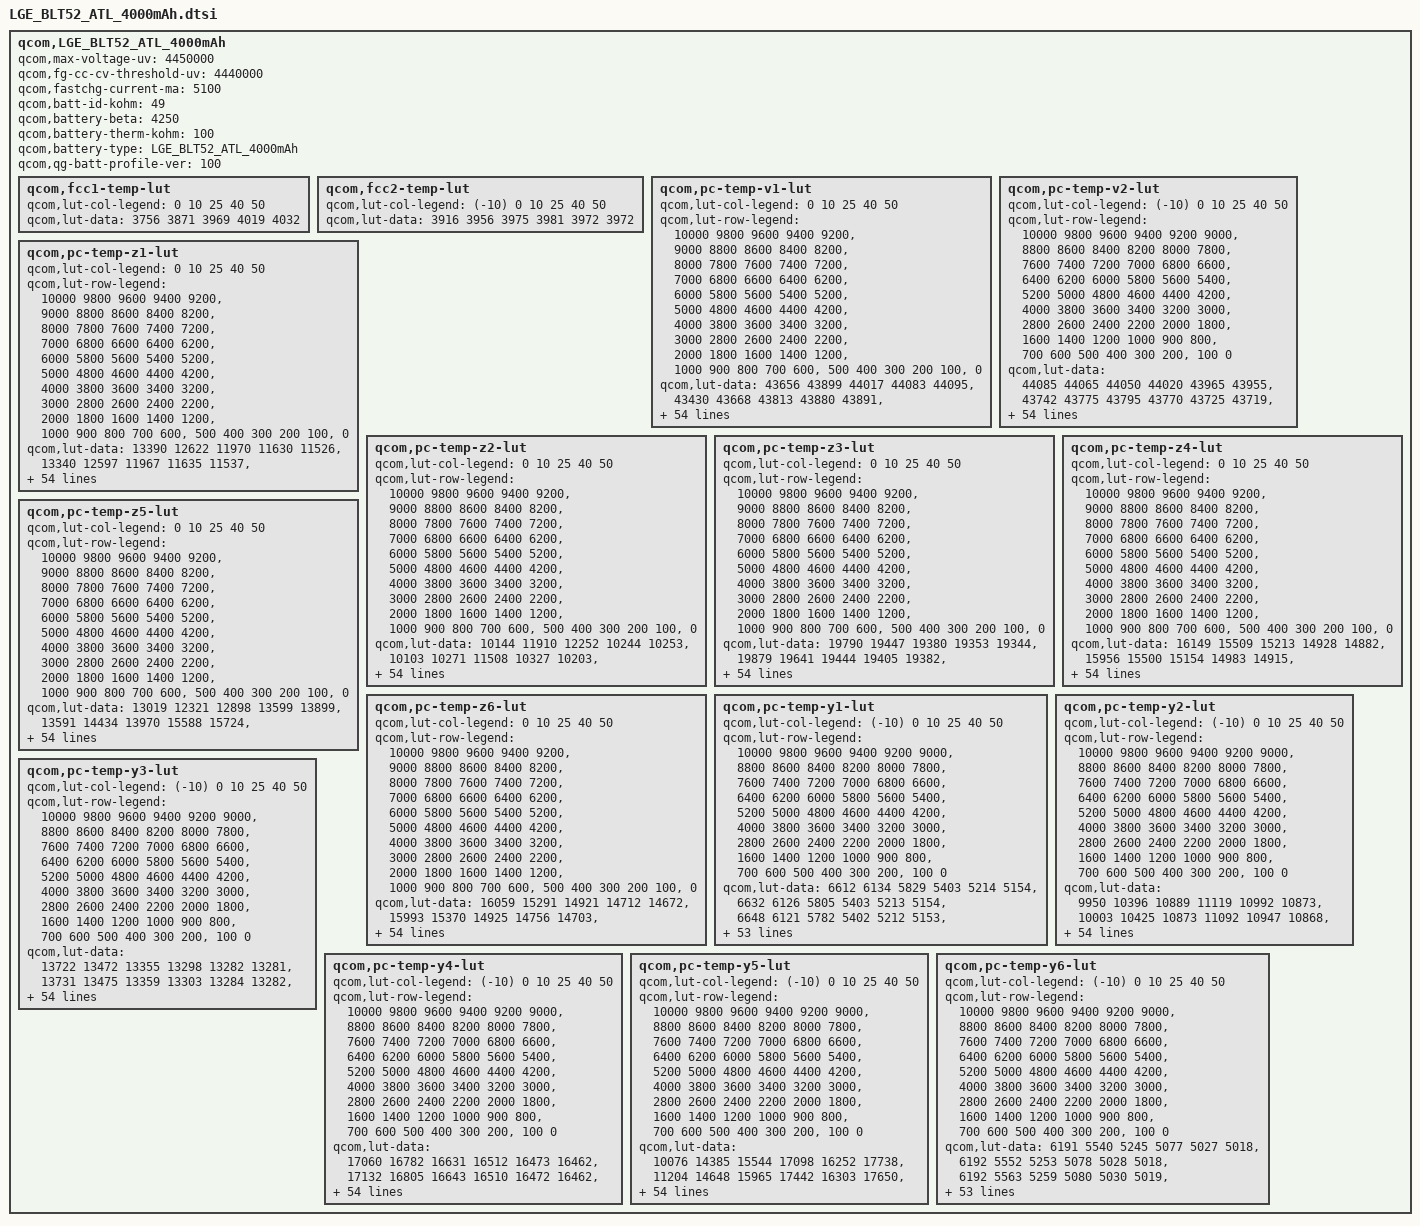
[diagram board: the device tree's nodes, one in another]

qcom,LGE_BLT52_ATL_4000mAh {
    /* 4569428_LGE_WingU_4000mAh_averaged_MasterSlave_Jun8th2020 */
    qcom,max-voltage-uv = <4450000>;
    qcom,fg-cc-cv-threshold-uv = <4440000>;
    qcom,fastchg-current-ma = <5100>;
    qcom,batt-id-kohm = <49>;
    qcom,battery-beta = <4250>;
    qcom,battery-therm-kohm = <100>;
    qcom,battery-type = "LGE_BLT52_ATL_4000mAh";
    qcom,qg-batt-profile-ver = <100>;

	qcom,fcc1-temp-lut {
		qcom,lut-col-legend = <0 10 25 40 50>;
		qcom,lut-data = <3756 3871 3969 4019 4032>;
	};

	qcom,fcc2-temp-lut {
		qcom,lut-col-legend = <(-10) 0 10 25 40 50>;
		qcom,lut-data = <3916 3956 3975 3981 3972 3972>;
	};

	qcom,pc-temp-v1-lut {
		qcom,lut-col-legend = <0 10 25 40 50>;
		qcom,lut-row-legend = <10000 9800 9600 9400 9200>,
			<9000 8800 8600 8400 8200>,
			<8000 7800 7600 7400 7200>,
			<7000 6800 6600 6400 6200>,
			<6000 5800 5600 5400 5200>,
			<5000 4800 4600 4400 4200>,
			<4000 3800 3600 3400 3200>,
			<3000 2800 2600 2400 2200>,
			<2000 1800 1600 1400 1200>,
			<1000 900 800 700 600>,
			<500 400 300 200 100>,
			<0>;
		qcom,lut-data = <43656 43899 44017 44083 44095>,
			<43430 43668 43813 43880 43891>,
			<43200 43445 43603 43676 43693>,
			<42968 43223 43383 43467 43489>,
			<42735 42994 43156 43251 43272>,
			<42502 42756 42923 43028 43048>,
			<42269 42518 42681 42795 42818>,
			<42040 42282 42438 42553 42581>,
			<41817 42047 42199 42312 42344>,
			<41599 41818 41960 42072 42104>,
			<41387 41595 41728 41835 41866>,
			<41180 41378 41501 41604 41635>,
			<40979 41166 41279 41377 41408>,
			<40782 40961 41064 41155 41186>,
			<40582 40759 40852 40937 40967>,
			<40388 40561 40650 40728 40756>,
			<40209 40369 40454 40527 40553>,
			<40040 40193 40267 40335 40357>,
			<39880 40032 40096 40153 40173>,
			<39733 39866 39938 39988 40006>,
			<39592 39689 39748 39812 39834>,
			<39435 39502 39475 39569 39607>,
			<39251 39291 39205 39289 39338>,
			<39064 39028 39029 39091 39133>,
			<38897 38813 38895 38958 38991>,
			<38736 38713 38784 38844 38868>,
			<38614 38648 38693 38734 38747>,
			<38541 38584 38612 38631 38635>,
			<38485 38519 38529 38535 38534>,
			<38436 38456 38448 38441 38442>,
			<38391 38396 38375 38356 38358>,
			<38351 38336 38308 38281 38279>,
			<38313 38283 38248 38213 38206>,
			<38280 38237 38192 38150 38137>,
			<38246 38195 38140 38094 38074>,
			<38213 38155 38092 38040 38011>,
			<38178 38120 38050 37986 37945>,
			<38133 38078 38008 37930 37876>,
			<38062 38007 37943 37859 37796>,
			<37974 37911 37850 37768 37700>,
			<37870 37805 37744 37664 37594>,
			<37741 37684 37628 37548 37479>,
			<37594 37545 37494 37415 37349>,
			<37429 37375 37330 37252 37185>,
			<37296 37222 37181 37111 37049>,
			<37206 37125 37080 37024 36964>,
			<37170 37097 37052 36997 36940>,
			<37136 37074 37035 36980 36923>,
			<37107 37058 37013 36963 36903>,
			<37056 37011 36975 36914 36847>,
			<36873 36815 36755 36675 36586>,
			<36436 36372 36321 36241 36152>,
			<35867 35793 35757 35673 35583>,
			<35085 34993 34985 34903 34813>,
			<33748 33648 33788 33709 33616>,
			<30000 30000 30000 30000 30000>;
	};

	qcom,pc-temp-v2-lut {
		qcom,lut-col-legend = <(-10) 0 10 25 40 50>;
		qcom,lut-row-legend = <10000 9800 9600 9400 9200 9000>,
			<8800 8600 8400 8200 8000 7800>,
			<7600 7400 7200 7000 6800 6600>,
			<6400 6200 6000 5800 5600 5400>,
			<5200 5000 4800 4600 4400 4200>,
			<4000 3800 3600 3400 3200 3000>,
			<2800 2600 2400 2200 2000 1800>,
			<1600 1400 1200 1000 900 800>,
			<700 600 500 400 300 200>,
			<100 0>;
		qcom,lut-data = <44085 44065 44050 44020 43965 43955>,
			<43742 43775 43795 43770 43725 43719>,
			<43429 43501 43546 43527 43489 43487>,
			<43151 43244 43305 43290 43257 43258>,
			<42908 43005 43075 43061 43031 43034>,
			<42670 42768 42841 42830 42803 42808>,
			<42416 42523 42599 42590 42567 42574>,
			<42160 42277 42355 42347 42328 42336>,
			<41923 42033 42113 42108 42091 42100>,
			<41705 41793 41873 41872 41855 41865>,
			<41494 41556 41638 41639 41623 41633>,
			<41281 41314 41409 41409 41396 41405>,
			<41067 41076 41185 41184 41174 41181>,
			<40840 40882 40972 40966 40958 40964>,
			<40594 40738 40770 40754 40745 40752>,
			<40332 40581 40571 40550 40540 40548>,
			<40050 40335 40371 40352 40344 40352>,
			<39746 40024 40168 40162 40157 40163>,
			<39482 39755 39944 39983 39976 39982>,
			<39271 39532 39689 39821 39810 39814>,
			<39084 39326 39443 39644 39631 39636>,
			<38901 39125 39231 39400 39398 39406>,
			<38724 38934 39039 39127 39137 39151>,
			<38568 38764 38870 38922 38936 38953>,
			<38431 38620 38720 38767 38783 38801>,
			<38313 38483 38585 38636 38654 38671>,
			<38224 38329 38463 38516 38539 38553>,
			<38157 38168 38352 38409 38437 38447>,
			<38098 38062 38251 38312 38343 38351>,
			<38040 38002 38159 38220 38253 38262>,
			<37985 37957 38072 38137 38171 38181>,
			<37930 37913 37983 38061 38100 38106>,
			<37874 37874 37897 37990 38036 38037>,
			<37816 37833 37834 37925 37968 37963>,
			<37759 37788 37792 37867 37894 37883>,
			<37701 37740 37753 37808 37815 37795>,
			<37638 37689 37712 37739 37724 37694>,
			<37571 37632 37670 37664 37622 37580>,
			<37499 37566 37616 37586 37526 37477>,
			<37415 37487 37542 37507 37441 37390>,
			<37320 37393 37450 37421 37355 37303>,
			<37229 37278 37339 37318 37254 37201>,
			<37146 37139 37201 37200 37140 37086>,
			<37064 37000 37035 37060 37006 36954>,
			<36984 36871 36884 36936 36895 36844>,
			<36893 36776 36796 36870 36844 36795>,
			<36845 36743 36766 36854 36832 36783>,
			<36797 36710 36732 36837 36819 36770>,
			<36738 36666 36683 36810 36797 36745>,
			<36661 36593 36588 36747 36724 36661>,
			<36533 36395 36359 36530 36476 36384>,
			<36266 35938 35912 36087 36005 35905>,
			<35775 35253 35275 35493 35405 35296>,
			<35022 34240 34380 34709 34593 34477>,
			<33889 32793 33037 33577 33438 33295>,
			<32352 29799 29518 29518 29519 29524>;
	};

	qcom,pc-temp-z1-lut {
		qcom,lut-col-legend = <0 10 25 40 50>;
		qcom,lut-row-legend = <10000 9800 9600 9400 9200>,
			<9000 8800 8600 8400 8200>,
			<8000 7800 7600 7400 7200>,
			<7000 6800 6600 6400 6200>,
			<6000 5800 5600 5400 5200>,
			<5000 4800 4600 4400 4200>,
			<4000 3800 3600 3400 3200>,
			<3000 2800 2600 2400 2200>,
			<2000 1800 1600 1400 1200>,
			<1000 900 800 700 600>,
			<500 400 300 200 100>,
			<0>;
		qcom,lut-data = <13390 12622 11970 11630 11526>,
			<13340 12597 11967 11635 11537>,
			<13314 12589 11963 11636 11539>,
			<13318 12581 11956 11635 11539>,
			<13326 12574 11947 11632 11538>,
			<13329 12568 11938 11629 11537>,
			<13312 12561 11929 11625 11536>,
			<13289 12548 11922 11622 11536>,
			<13278 12531 11917 11620 11536>,
			<13272 12522 11913 11619 11536>,
			<13267 12519 11911 11618 11536>,
			<13261 12517 11910 11618 11536>,
			<13255 12512 11909 11618 11538>,
			<13250 12504 11910 11618 11539>,
			<13242 12500 11911 11619 11539>,
			<13234 12500 11913 11620 11540>,
			<13231 12502 11913 11622 11541>,
			<13233 12502 11914 11623 11544>,
			<13235 12500 11916 11625 11547>,
			<13234 12499 11920 11628 11549>,
			<13230 12503 11923 11630 11551>,
			<13228 12509 11926 11632 11552>,
			<13223 12515 11929 11634 11554>,
			<13221 12523 11933 11636 11556>,
			<13227 12529 11938 11640 11559>,
			<13247 12531 11943 11644 11562>,
			<13260 12533 11948 11648 11566>,
			<13252 12534 11954 11652 11569>,
			<13239 12535 11960 11657 11573>,
			<13235 12536 11966 11660 11577>,
			<13239 12537 11971 11664 11581>,
			<13248 12539 11977 11669 11585>,
			<13263 12541 11981 11673 11590>,
			<13289 12546 11986 11677 11593>,
			<13305 12553 11991 11682 11597>,
			<13296 12562 11996 11686 11600>,
			<13280 12575 12000 11690 11602>,
			<13275 12584 12004 11693 11605>,
			<13286 12588 12010 11696 11607>,
			<13299 12591 12017 11700 11610>,
			<13307 12593 12025 11704 11613>,
			<13312 12603 12038 11707 11616>,
			<13325 12612 12047 11711 11619>,
			<13350 12619 12050 11715 11621>,
			<13330 12636 12058 11722 11625>,
			<13344 12624 12069 11725 11627>,
			<13344 12630 12071 11724 11627>,
			<13331 12621 12071 11725 11627>,
			<13345 12624 12074 11726 11628>,
			<13364 12623 12080 11730 11631>,
			<13365 12636 12090 11734 11636>,
			<13377 12654 12093 11745 11644>,
			<13396 12702 12112 11757 11654>,
			<13442 12722 12139 11776 11669>,
			<13442 12722 12139 11776 11669>,
			<13442 12722 12139 11776 11669>;
	};

	qcom,pc-temp-z2-lut {
		qcom,lut-col-legend = <0 10 25 40 50>;
		qcom,lut-row-legend = <10000 9800 9600 9400 9200>,
			<9000 8800 8600 8400 8200>,
			<8000 7800 7600 7400 7200>,
			<7000 6800 6600 6400 6200>,
			<6000 5800 5600 5400 5200>,
			<5000 4800 4600 4400 4200>,
			<4000 3800 3600 3400 3200>,
			<3000 2800 2600 2400 2200>,
			<2000 1800 1600 1400 1200>,
			<1000 900 800 700 600>,
			<500 400 300 200 100>,
			<0>;
		qcom,lut-data = <10144 11910 12252 10244 10253>,
			<10103 10271 11508 10327 10203>,
			<10069 10230 11015 10367 10279>,
			<10040 10206 10822 10413 10321>,
			<10015 10178 10690 10599 10306>,
			<10001 10145 10543 10764 10276>,
			<9993 10119 10348 10641 10238>,
			<9987 10103 10220 10331 10187>,
			<9984 10091 10212 10235 10165>,
			<9982 10088 10214 10459 10180>,
			<9981 10091 10228 10673 10198>,
			<9982 10096 10348 10671 10177>,
			<9985 10111 10476 10640 10101>,
			<9988 10147 10519 10631 10067>,
			<9991 10176 10547 10661 10080>,
			<9997 10192 10552 10702 10098>,
			<10012 10205 10443 10743 10109>,
			<10049 10222 10333 10788 10120>,
			<10084 10241 10335 10772 10133>,
			<10104 10256 10350 10478 10151>,
			<10120 10262 10366 10220 10176>,
			<10132 10267 10394 10277 10232>,
			<10139 10272 10418 10414 10325>,
			<10146 10279 10402 10443 10360>,
			<10153 10284 10345 10335 10326>,
			<10162 10280 10321 10245 10298>,
			<10170 10268 10351 10300 10372>,
			<10178 10264 10393 10419 10519>,
			<10186 10275 10416 10468 10551>,
			<10193 10291 10434 10467 10393>,
			<10200 10300 10440 10447 10224>,
			<10207 10308 10420 10392 10155>,
			<10215 10312 10395 10320 10106>,
			<10225 10313 10393 10305 10099>,
			<10232 10315 10395 10323 10127>,
			<10238 10316 10400 10352 10170>,
			<10243 10321 10409 10397 10226>,
			<10250 10328 10423 10455 10293>,
			<10263 10341 10442 10491 10339>,
			<10279 10361 10470 10513 10375>,
			<10296 10375 10494 10532 10392>,
			<10315 10381 10509 10554 10385>,
			<10343 10391 10518 10568 10373>,
			<10392 10425 10518 10557 10400>,
			<10593 10639 10586 10520 10394>,
			<10375 10685 10618 10424 10353>,
			<10307 10709 10595 10402 10351>,
			<10266 10759 10584 10398 10355>,
			<10227 11049 10584 10435 10379>,
			<10192 11104 10621 10515 10483>,
			<10162 11055 10704 10502 10338>,
			<10063 10905 10677 10305 10137>,
			<9871 10760 10807 10240 10102>,
			<9781 10475 10800 10187 10036>,
			<9781 10475 10800 10187 10036>,
			<9781 10475 10800 10187 10036>;
	};

	qcom,pc-temp-z3-lut {
		qcom,lut-col-legend = <0 10 25 40 50>;
		qcom,lut-row-legend = <10000 9800 9600 9400 9200>,
			<9000 8800 8600 8400 8200>,
			<8000 7800 7600 7400 7200>,
			<7000 6800 6600 6400 6200>,
			<6000 5800 5600 5400 5200>,
			<5000 4800 4600 4400 4200>,
			<4000 3800 3600 3400 3200>,
			<3000 2800 2600 2400 2200>,
			<2000 1800 1600 1400 1200>,
			<1000 900 800 700 600>,
			<500 400 300 200 100>,
			<0>;
		qcom,lut-data = <19790 19447 19380 19353 19344>,
			<19879 19641 19444 19405 19382>,
			<19936 19678 19490 19429 19398>,
			<19958 19698 19518 19444 19409>,
			<19971 19707 19539 19458 19419>,
			<19978 19712 19544 19466 19427>,
			<19982 19715 19539 19462 19428>,
			<19984 19714 19533 19453 19428>,
			<19982 19713 19527 19450 19428>,
			<19970 19710 19520 19457 19425>,
			<19959 19699 19516 19464 19418>,
			<19953 19683 19517 19457 19410>,
			<19948 19669 19518 19445 19400>,
			<19947 19653 19514 19438 19392>,
			<19950 19642 19509 19434 19388>,
			<19953 19636 19501 19431 19385>,
			<19946 19631 19484 19427 19382>,
			<19912 19627 19468 19421 19379>,
			<19885 19624 19461 19414 19376>,
			<19879 19623 19456 19396 19369>,
			<19876 19626 19456 19383 19364>,
			<19876 19634 19479 19390 19367>,
			<19887 19643 19504 19405 19375>,
			<19899 19655 19499 19407 19377>,
			<19900 19663 19477 19382 19357>,
			<19899 19657 19459 19361 19339>,
			<19897 19641 19448 19367 19360>,
			<19890 19630 19441 19381 19412>,
			<19878 19624 19446 19394 19428>,
			<19867 19621 19464 19418 19421>,
			<19859 19623 19478 19435 19412>,
			<19851 19630 19485 19432 19403>,
			<19843 19635 19490 19424 19395>,
			<19835 19634 19490 19416 19386>,
			<19827 19631 19486 19407 19377>,
			<19820 19628 19481 19399 19370>,
			<19814 19622 19474 19394 19368>,
			<19807 19616 19466 19389 19366>,
			<19797 19609 19460 19385 19365>,
			<19785 19602 19456 19380 19363>,
			<19771 19594 19452 19377 19363>,
			<19752 19586 19450 19382 19363>,
			<19730 19575 19447 19388 19365>,
			<19697 19560 19438 19387 19371>,
			<19477 19506 19418 19379 19368>,
			<19338 19483 19412 19360 19354>,
			<19328 19465 19411 19359 19346>,
			<19325 19441 19399 19358 19342>,
			<19317 19314 19400 19348 19335>,
			<19310 19311 19366 19339 19330>,
			<19311 19317 19369 19343 19352>,
			<19325 19315 19371 19364 19364>,
			<19335 19315 19329 19367 19367>,
			<19360 19350 19326 19368 19366>,
			<19360 19350 19326 19368 19366>,
			<19360 19350 19326 19368 19366>;
	};

	qcom,pc-temp-z4-lut {
		qcom,lut-col-legend = <0 10 25 40 50>;
		qcom,lut-row-legend = <10000 9800 9600 9400 9200>,
			<9000 8800 8600 8400 8200>,
			<8000 7800 7600 7400 7200>,
			<7000 6800 6600 6400 6200>,
			<6000 5800 5600 5400 5200>,
			<5000 4800 4600 4400 4200>,
			<4000 3800 3600 3400 3200>,
			<3000 2800 2600 2400 2200>,
			<2000 1800 1600 1400 1200>,
			<1000 900 800 700 600>,
			<500 400 300 200 100>,
			<0>;
		qcom,lut-data = <16149 15509 15213 14928 14882>,
			<15956 15500 15154 14983 14915>,
			<15784 15412 15095 14950 14894>,
			<15633 15267 15028 14913 14870>,
			<15497 15168 14960 14863 14845>,
			<15385 15095 14918 14822 14819>,
			<15291 15035 14893 14809 14797>,
			<15213 14985 14871 14800 14778>,
			<15154 14943 14845 14789 14762>,
			<15108 14912 14816 14752 14748>,
			<15067 14890 14792 14717 14738>,
			<15028 14871 14765 14711 14734>,
			<14992 14852 14742 14709 14733>,
			<14959 14833 14732 14705 14730>,
			<14925 14821 14722 14696 14724>,
			<14897 14816 14718 14687 14715>,
			<14883 14812 14728 14680 14708>,
			<14876 14803 14739 14675 14701>,
			<14868 14785 14735 14673 14695>,
			<14848 14775 14728 14681 14691>,
			<14823 14778 14727 14696 14689>,
			<14816 14785 14774 14736 14713>,
			<14830 14803 14838 14806 14785>,
			<14854 14878 14874 14847 14830>,
			<14883 14939 14901 14872 14852>,
			<14925 14937 14910 14884 14863>,
			<14949 14924 14903 14872 14834>,
			<14945 14909 14890 14839 14760>,
			<14934 14893 14870 14806 14726>,
			<14922 14876 14837 14761 14718>,
			<14910 14857 14808 14728 14712>,
			<14895 14836 14783 14718 14707>,
			<14881 14820 14763 14712 14701>,
			<14866 14809 14755 14710 14699>,
			<14852 14801 14751 14710 14697>,
			<14837 14792 14749 14710 14697>,
			<14823 14784 14749 14712 14698>,
			<14812 14779 14749 14716 14702>,
			<14802 14780 14751 14722 14708>,
			<14794 14781 14762 14736 14720>,
			<14787 14780 14768 14744 14728>,
			<14781 14767 14756 14732 14722>,
			<14771 14752 14744 14719 14713>,
			<14758 14741 14741 14719 14711>,
			<14852 14711 14719 14709 14701>,
			<14983 14704 14695 14700 14686>,
			<14988 14711 14685 14691 14685>,
			<14987 14727 14677 14674 14669>,
			<14988 14859 14660 14659 14652>,
			<14987 14857 14690 14661 14647>,
			<14980 14855 14710 14692 14667>,
			<14992 14873 14722 14683 14667>,
			<14999 14876 14770 14682 14666>,
			<15000 14855 14775 14681 14667>,
			<15000 14855 14775 14681 14667>,
			<15000 14855 14775 14681 14667>;
	};

	qcom,pc-temp-z5-lut {
		qcom,lut-col-legend = <0 10 25 40 50>;
		qcom,lut-row-legend = <10000 9800 9600 9400 9200>,
			<9000 8800 8600 8400 8200>,
			<8000 7800 7600 7400 7200>,
			<7000 6800 6600 6400 6200>,
			<6000 5800 5600 5400 5200>,
			<5000 4800 4600 4400 4200>,
			<4000 3800 3600 3400 3200>,
			<3000 2800 2600 2400 2200>,
			<2000 1800 1600 1400 1200>,
			<1000 900 800 700 600>,
			<500 400 300 200 100>,
			<0>;
		qcom,lut-data = <13019 12321 12898 13599 13899>,
			<13591 14434 13970 15588 15724>,
			<14057 15037 14876 16657 16550>,
			<14386 15420 15636 17338 17217>,
			<14654 15831 16300 17935 17926>,
			<14976 16226 16684 18324 18532>,
			<15423 16645 16886 18267 18927>,
			<15877 17223 17097 17979 19198>,
			<16194 17858 17526 18173 19509>,
			<16417 18189 18148 21527 20047>,
			<16686 18302 18713 24683 20493>,
			<17113 18413 20294 24501 20241>,
			<17723 18726 22039 23699 19300>,
			<18589 19332 23106 23514 18893>,
			<20511 19942 24132 24779 19199>,
			<22294 20461 24511 26465 19725>,
			<22524 21006 22756 27848 20403>,
			<22462 21630 21010 29150 21333>,
			<22419 22329 21250 29245 21887>,
			<23293 23379 21897 25245 22092>,
			<25722 26252 23404 21798 22169>,
			<29130 30612 33792 24177 22836>,
			<37016 33992 44539 29124 24542>,
			<44344 37052 41898 29803 24685>,
			<45177 38852 30277 22613 19626>,
			<44612 36360 22826 16360 14887>,
			<43731 29898 19925 15932 16339>,
			<41484 26364 18283 16099 20443>,
			<37956 25158 18436 16900 22130>,
			<35623 24502 19701 20002 22059>,
			<34175 25015 21283 23037 21951>,
			<33181 27253 23549 24425 22351>,
			<32718 29381 26198 25408 22984>,
			<32356 30938 28570 25985 23433>,
			<32199 32201 30965 26406 23709>,
			<32455 32764 31936 26602 23979>,
			<33021 33097 31325 26419 24422>,
			<33613 33246 30178 25903 24894>,
			<34719 33115 28907 24984 24746>,
			<35682 32719 27240 22750 22793>,
			<35091 32057 26048 21299 21126>,
			<32728 30325 25597 21929 20784>,
			<31513 29056 25069 22657 20640>,
			<30808 28397 23091 22366 22234>,
			<18969 28760 23495 21989 22218>,
			<12331 26052 24841 19242 19833>,
			<12126 21622 24929 19476 18170>,
			<12047 19848 22718 20717 18664>,
			<11914 12239 25100 20961 20429>,
			<11836 12199 17190 19683 21051>,
			<11936 12413 16639 16375 20048>,
			<11978 12175 15610 17202 19634>,
			<11908 12110 12894 17134 19164>,
			<12603 13070 12639 16466 17681>,
			<12603 13070 12639 16466 17681>,
			<12603 13070 12639 16466 17681>;
	};

	qcom,pc-temp-z6-lut {
		qcom,lut-col-legend = <0 10 25 40 50>;
		qcom,lut-row-legend = <10000 9800 9600 9400 9200>,
			<9000 8800 8600 8400 8200>,
			<8000 7800 7600 7400 7200>,
			<7000 6800 6600 6400 6200>,
			<6000 5800 5600 5400 5200>,
			<5000 4800 4600 4400 4200>,
			<4000 3800 3600 3400 3200>,
			<3000 2800 2600 2400 2200>,
			<2000 1800 1600 1400 1200>,
			<1000 900 800 700 600>,
			<500 400 300 200 100>,
			<0>;
		qcom,lut-data = <16059 15291 14921 14712 14672>,
			<15993 15370 14925 14756 14703>,
			<15927 15337 14921 14757 14704>,
			<15857 15276 14908 14757 14704>,
			<15787 15231 14886 14746 14700>,
			<15727 15194 14867 14731 14692>,
			<15677 15161 14852 14722 14685>,
			<15634 15134 14837 14714 14678>,
			<15597 15110 14821 14705 14670>,
			<15564 15089 14805 14694 14662>,
			<15536 15069 14791 14684 14655>,
			<15511 15051 14780 14676 14648>,
			<15489 15033 14771 14669 14642>,
			<15469 15015 14763 14663 14636>,
			<15453 15003 14757 14657 14631>,
			<15437 14997 14751 14651 14626>,
			<15418 14992 14746 14646 14621>,
			<15396 14985 14741 14641 14616>,
			<15378 14977 14736 14636 14611>,
			<15366 14972 14731 14631 14606>,
			<15356 14975 14730 14629 14603>,
			<15354 14983 14766 14648 14616>,
			<15367 14998 14806 14691 14654>,
			<15385 15038 14813 14704 14668>,
			<15402 15070 14815 14702 14668>,
			<15421 15067 14815 14700 14667>,
			<15432 15054 14809 14697 14665>,
			<15427 15043 14800 14692 14662>,
			<15417 15035 14795 14687 14658>,
			<15408 15027 14791 14682 14652>,
			<15401 15022 14787 14676 14645>,
			<15394 15017 14782 14671 14638>,
			<15386 15013 14777 14665 14632>,
			<15377 15010 14773 14660 14626>,
			<15369 15008 14771 14655 14620>,
			<15362 15004 14768 14652 14617>,
			<15356 14999 14764 14650 14617>,
			<15352 14996 14761 14649 14617>,
			<15349 14996 14761 14649 14618>,
			<15347 14997 14765 14653 14623>,
			<15344 14996 14767 14655 14626>,
			<15339 14991 14763 14653 14624>,
			<15332 14984 14757 14651 14621>,
			<15319 14978 14754 14651 14624>,
			<15254 14949 14738 14644 14619>,
			<15249 14934 14726 14630 14605>,
			<15248 14929 14722 14625 14601>,
			<15246 14925 14712 14617 14592>,
			<15246 14920 14707 14606 14580>,
			<15248 14920 14703 14602 14575>,
			<15254 14931 14716 14619 14597>,
			<15280 14944 14726 14629 14607>,
			<15303 14957 14730 14633 14610>,
			<15345 14983 14738 14637 14614>,
			<15345 14983 14738 14637 14614>,
			<15345 14983 14738 14637 14614>;
	};

	qcom,pc-temp-y1-lut {
		qcom,lut-col-legend = <(-10) 0 10 25 40 50>;
		qcom,lut-row-legend = <10000 9800 9600 9400 9200 9000>,
			<8800 8600 8400 8200 8000 7800>,
			<7600 7400 7200 7000 6800 6600>,
			<6400 6200 6000 5800 5600 5400>,
			<5200 5000 4800 4600 4400 4200>,
			<4000 3800 3600 3400 3200 3000>,
			<2800 2600 2400 2200 2000 1800>,
			<1600 1400 1200 1000 900 800>,
			<700 600 500 400 300 200>,
			<100 0>;
		qcom,lut-data = <6612 6134 5829 5403 5214 5154>,
			<6632 6126 5805 5403 5213 5154>,
			<6648 6121 5782 5402 5212 5153>,
			<6662 6119 5764 5401 5210 5153>,
			<6672 6119 5751 5400 5209 5152>,
			<6678 6122 5746 5399 5208 5152>,
			<6681 6129 5751 5396 5207 5151>,
			<6681 6137 5759 5392 5206 5151>,
			<6679 6138 5760 5388 5205 5150>,
			<6670 6126 5752 5384 5204 5150>,
			<6661 6116 5743 5381 5204 5150>,
			<6662 6118 5737 5382 5203 5151>,
			<6663 6123 5730 5383 5203 5152>,
			<6665 6125 5728 5383 5202 5152>,
			<6680 6120 5729 5382 5203 5152>,
			<6697 6118 5729 5382 5204 5151>,
			<6700 6123 5730 5382 5204 5152>,
			<6701 6131 5731 5383 5205 5153>,
			<6701 6135 5733 5384 5206 5154>,
			<6699 6135 5736 5386 5207 5156>,
			<6698 6135 5740 5388 5208 5157>,
			<6703 6134 5745 5391 5210 5158>,
			<6710 6131 5750 5395 5212 5159>,
			<6713 6131 5751 5399 5214 5161>,
			<6708 6138 5751 5402 5216 5163>,
			<6696 6145 5752 5406 5219 5165>,
			<6686 6146 5757 5411 5221 5167>,
			<6674 6146 5764 5416 5224 5168>,
			<6667 6146 5766 5421 5227 5171>,
			<6679 6148 5766 5426 5230 5174>,
			<6702 6150 5765 5431 5233 5177>,
			<6712 6150 5766 5436 5236 5179>,
			<6715 6149 5766 5442 5240 5182>,
			<6717 6150 5768 5446 5244 5184>,
			<6723 6162 5773 5449 5247 5187>,
			<6733 6175 5779 5452 5250 5189>,
			<6734 6173 5782 5457 5252 5190>,
			<6707 6161 5786 5462 5254 5192>,
			<6681 6156 5790 5465 5256 5193>,
			<6680 6158 5794 5467 5257 5195>,
			<6684 6161 5797 5470 5259 5197>,
			<6687 6167 5801 5473 5261 5199>,
			<6688 6182 5805 5479 5263 5200>,
			<6690 6183 5804 5491 5266 5201>,
			<6706 6184 5803 5500 5269 5203>,
			<6729 6182 5811 5506 5273 5207>,
			<6746 6202 5816 5505 5273 5207>,
			<6768 6203 5824 5506 5273 5207>,
			<6783 6239 5825 5504 5273 5207>,
			<6821 6239 5834 5505 5274 5208>,
			<6878 6276 5847 5507 5274 5210>,
			<6973 6326 5858 5520 5280 5215>,
			<7038 6366 5907 5540 5289 5223>,
			<7187 6520 5952 5566 5300 5231>,
			<7187 6520 5952 5566 5300 5231>,
			<7187 6520 5952 5566 5300 5231>;
	};

	qcom,pc-temp-y2-lut {
		qcom,lut-col-legend = <(-10) 0 10 25 40 50>;
		qcom,lut-row-legend = <10000 9800 9600 9400 9200 9000>,
			<8800 8600 8400 8200 8000 7800>,
			<7600 7400 7200 7000 6800 6600>,
			<6400 6200 6000 5800 5600 5400>,
			<5200 5000 4800 4600 4400 4200>,
			<4000 3800 3600 3400 3200 3000>,
			<2800 2600 2400 2200 2000 1800>,
			<1600 1400 1200 1000 900 800>,
			<700 600 500 400 300 200>,
			<100 0>;
		qcom,lut-data = <9950 10396 10889 11119 10992 10873>,
			<10003 10425 10873 11092 10947 10868>,
			<10053 10459 10858 11063 10903 10855>,
			<10101 10494 10842 11033 10865 10836>,
			<10146 10523 10827 11004 10837 10814>,
			<10187 10541 10812 10978 10821 10793>,
			<10220 10549 10795 10951 10818 10766>,
			<10250 10555 10780 10926 10822 10737>,
			<10307 10553 10778 10918 10821 10718>,
			<10449 10536 10785 10915 10810 10701>,
			<10560 10523 10796 10914 10807 10692>,
			<10552 10595 10808 10924 10832 10697>,
			<10520 10737 10827 10948 10872 10705>,
			<10514 10775 10853 10975 10894 10713>,
			<10618 10756 10898 11010 10905 10743>,
			<10730 10741 10947 11048 10918 10774>,
			<10559 10760 10999 11082 10948 10802>,
			<9988 10812 11048 11118 11000 10852>,
			<9701 10853 11057 11173 11070 10919>,
			<9691 10880 11047 11276 11193 11042>,
			<9685 10906 11040 11342 11276 11126>,
			<9682 10942 11047 11291 11239 11094>,
			<9680 10982 11065 11193 11151 11024>,
			<9677 10990 11080 11170 11102 11003>,
			<9674 10926 11091 11188 11077 11005>,
			<9671 10861 11104 11211 11063 11011>,
			<9670 10867 11128 11229 11104 11030>,
			<9668 10896 11157 11247 11198 11071>,
			<9667 10907 11163 11267 11240 11110>,
			<9667 10873 11141 11291 11242 11156>,
			<9666 10800 11118 11314 11244 11203>,
			<9665 10556 11112 11337 11297 11245>,
			<9664 10003 11109 11360 11397 11283>,
			<9664 9729 11101 11365 11430 11304>,
			<9663 9702 11077 11354 11422 11325>,
			<9663 9687 11043 11338 11407 11337>,
			<9663 9678 11012 11318 11353 11302>,
			<9662 9672 10978 11290 11243 11214>,
			<9662 9668 10937 11261 11197 11146>,
			<9662 9665 10887 11233 11203 11094>,
			<9661 9663 10824 11202 11213 11061>,
			<9661 9662 10751 11166 11214 11067>,
			<9660 9660 10643 11125 11212 11083>,
			<9660 9659 10232 11078 11155 11050>,
			<9659 9659 9815 11008 11021 10935>,
			<9657 9658 9763 10973 10908 10794>,
			<9656 9657 9757 10985 10907 10784>,
			<9655 9657 9707 10966 10965 10780>,
			<9653 9656 9683 10951 10987 10864>,
			<9651 9654 9671 10948 11000 10867>,
			<9649 9652 9663 10926 10949 10776>,
			<9648 9649 9658 10842 10879 10723>,
			<9648 9648 9653 10755 10852 10653>,
			<9647 9648 9650 10664 10743 10543>,
			<9647 9648 9650 10664 10743 10543>,
			<9647 9648 9650 10664 10743 10543>;
	};

	qcom,pc-temp-y3-lut {
		qcom,lut-col-legend = <(-10) 0 10 25 40 50>;
		qcom,lut-row-legend = <10000 9800 9600 9400 9200 9000>,
			<8800 8600 8400 8200 8000 7800>,
			<7600 7400 7200 7000 6800 6600>,
			<6400 6200 6000 5800 5600 5400>,
			<5200 5000 4800 4600 4400 4200>,
			<4000 3800 3600 3400 3200 3000>,
			<2800 2600 2400 2200 2000 1800>,
			<1600 1400 1200 1000 900 800>,
			<700 600 500 400 300 200>,
			<100 0>;
		qcom,lut-data = <13722 13472 13355 13298 13282 13281>,
			<13731 13475 13359 13303 13284 13282>,
			<13735 13477 13364 13307 13285 13283>,
			<13735 13480 13369 13309 13287 13284>,
			<13733 13482 13373 13311 13288 13285>,
			<13728 13484 13376 13312 13290 13286>,
			<13714 13484 13377 13312 13291 13287>,
			<13690 13484 13379 13311 13292 13288>,
			<13681 13483 13379 13311 13294 13289>,
			<13681 13477 13379 13315 13294 13290>,
			<13680 13470 13379 13317 13296 13291>,
			<13648 13461 13376 13318 13299 13292>,
			<13580 13451 13372 13318 13303 13293>,
			<13554 13449 13370 13318 13304 13294>,
			<13560 13452 13368 13320 13304 13296>,
			<13566 13455 13367 13321 13304 13297>,
			<13555 13451 13369 13318 13305 13298>,
			<13521 13441 13373 13313 13307 13299>,
			<13504 13432 13373 13312 13307 13299>,
			<13504 13423 13364 13319 13304 13298>,
			<13504 13415 13355 13324 13301 13297>,
			<13506 13405 13351 13320 13296 13292>,
			<13515 13394 13347 13310 13291 13286>,
			<13520 13387 13344 13306 13287 13284>,
			<13515 13383 13342 13304 13285 13283>,
			<13507 13379 13340 13303 13284 13283>,
			<13509 13367 13338 13303 13285 13282>,
			<13530 13348 13336 13302 13286 13282>,
			<13559 13341 13336 13302 13286 13282>,
			<13588 13344 13335 13302 13285 13283>,
			<13624 13349 13335 13302 13284 13284>,
			<13659 13358 13334 13302 13285 13283>,
			<13695 13377 13332 13301 13288 13283>,
			<13733 13396 13331 13301 13289 13283>,
			<13775 13416 13333 13303 13289 13283>,
			<13820 13438 13336 13304 13288 13284>,
			<13862 13469 13339 13303 13286 13283>,
			<13904 13509 13343 13302 13285 13282>,
			<13942 13557 13346 13302 13285 13281>,
			<13975 13616 13350 13302 13286 13283>,
			<14003 13685 13353 13303 13287 13284>,
			<14036 13758 13356 13304 13288 13285>,
			<14077 13837 13359 13306 13289 13285>,
			<14129 13914 13362 13307 13287 13284>,
			<14203 13990 13372 13309 13285 13282>,
			<14391 14063 13392 13311 13290 13288>,
			<14506 14053 13396 13312 13293 13290>,
			<14581 14164 13432 13317 13299 13294>,
			<15067 14310 13479 13324 13302 13296>,
			<15930 14633 13551 13329 13302 13295>,
			<17884 15308 13678 13326 13296 13290>,
			<22643 17186 13957 13326 13294 13289>,
			<36108 23402 14644 13335 13300 13293>,
			<65535 47011 16544 13350 13305 13300>,
			<65535 47011 16544 13350 13305 13300>,
			<65535 47011 16544 13350 13305 13300>;
	};

	qcom,pc-temp-y4-lut {
		qcom,lut-col-legend = <(-10) 0 10 25 40 50>;
		qcom,lut-row-legend = <10000 9800 9600 9400 9200 9000>,
			<8800 8600 8400 8200 8000 7800>,
			<7600 7400 7200 7000 6800 6600>,
			<6400 6200 6000 5800 5600 5400>,
			<5200 5000 4800 4600 4400 4200>,
			<4000 3800 3600 3400 3200 3000>,
			<2800 2600 2400 2200 2000 1800>,
			<1600 1400 1200 1000 900 800>,
			<700 600 500 400 300 200>,
			<100 0>;
		qcom,lut-data = <17060 16782 16631 16512 16473 16462>,
			<17132 16805 16643 16510 16472 16462>,
			<17200 16855 16661 16509 16472 16462>,
			<17258 16912 16680 16510 16472 16462>,
			<17299 16961 16695 16511 16472 16463>,
			<17316 16982 16701 16513 16473 16463>,
			<17308 16981 16700 16518 16474 16464>,
			<17286 16980 16697 16525 16475 16465>,
			<17260 16980 16697 16528 16477 16466>,
			<17217 16990 16702 16530 16482 16468>,
			<17186 17003 16709 16532 16485 16470>,
			<17227 17015 16723 16539 16486 16474>,
			<17331 17028 16743 16550 16487 16479>,
			<17365 17048 16767 16561 16489 16483>,
			<17238 17091 16801 16573 16498 16488>,
			<17098 17121 16821 16587 16509 16492>,
			<17078 17071 16816 16615 16520 16498>,
			<17074 16948 16801 16648 16532 16508>,
			<17066 16874 16777 16663 16550 16522>,
			<17031 16840 16726 16672 16586 16551>,
			<16975 16813 16675 16675 16611 16572>,
			<16917 16782 16641 16632 16580 16550>,
			<16845 16752 16613 16547 16514 16502>,
			<16810 16724 16599 16515 16487 16479>,
			<16815 16699 16590 16506 16480 16471>,
			<16824 16676 16584 16502 16477 16467>,
			<16827 16650 16581 16504 16479 16469>,
			<16826 16622 16579 16509 16484 16475>,
			<16824 16613 16576 16515 16491 16481>,
			<16820 16618 16571 16521 16502 16488>,
			<16814 16627 16564 16528 16515 16497>,
			<16814 16645 16552 16537 16524 16508>,
			<16821 16679 16536 16545 16533 16522>,
			<16827 16707 16532 16548 16535 16526>,
			<16829 16727 16544 16548 16534 16523>,
			<16829 16742 16563 16548 16531 16518>,
			<16829 16755 16583 16541 16519 16507>,
			<16824 16766 16607 16524 16496 16489>,
			<16819 16770 16626 16518 16485 16482>,
			<16817 16769 16641 16516 16484 16481>,
			<16816 16767 16651 16516 16483 16481>,
			<16816 16758 16650 16520 16483 16480>,
			<16819 16734 16648 16527 16483 16480>,
			<16826 16718 16653 16524 16475 16468>,
			<16843 16709 16660 16521 16467 16454>,
			<16905 16714 16656 16514 16470 16461>,
			<16929 16704 16654 16515 16481 16481>,
			<16894 16718 16680 16532 16502 16511>,
			<17012 16743 16715 16558 16534 16544>,
			<17225 16832 16758 16589 16547 16547>,
			<17649 16990 16774 16567 16509 16494>,
			<18633 17348 16785 16548 16474 16469>,
			<22719 19603 16955 16562 16475 16471>,
			<55470 45558 18096 16605 16494 16485>,
			<55470 45558 18096 16605 16494 16485>,
			<55470 45558 18096 16605 16494 16485>;
	};

	qcom,pc-temp-y5-lut {
		qcom,lut-col-legend = <(-10) 0 10 25 40 50>;
		qcom,lut-row-legend = <10000 9800 9600 9400 9200 9000>,
			<8800 8600 8400 8200 8000 7800>,
			<7600 7400 7200 7000 6800 6600>,
			<6400 6200 6000 5800 5600 5400>,
			<5200 5000 4800 4600 4400 4200>,
			<4000 3800 3600 3400 3200 3000>,
			<2800 2600 2400 2200 2000 1800>,
			<1600 1400 1200 1000 900 800>,
			<700 600 500 400 300 200>,
			<100 0>;
		qcom,lut-data = <10076 14385 15544 17098 16252 17738>,
			<11204 14648 15965 17442 16303 17650>,
			<12453 14909 16294 17531 16315 17555>,
			<13672 15153 16532 17419 16294 17455>,
			<14707 15366 16676 17158 16251 17352>,
			<15405 15535 16727 16801 16191 17249>,
			<15724 15680 16647 16022 16105 17153>,
			<15938 15793 16459 15068 15980 17048>,
			<16452 15794 16238 14808 15789 16902>,
			<18172 15610 15926 14979 15425 16687>,
			<19576 15357 15600 15054 15197 16419>,
			<19004 15013 15251 14708 15628 16032>,
			<17459 14617 14936 14235 16402 15588>,
			<17038 14813 14899 14056 16496 15354>,
			<20250 17493 15167 13998 15749 15397>,
			<23666 19828 15655 13952 15052 15487>,
			<22223 19925 17741 13879 14822 15270>,
			<16730 19844 20984 13804 14674 14859>,
			<14065 19903 21781 14409 14686 14792>,
			<14242 20282 21514 18696 15106 14848>,
			<14490 20602 21231 21953 15768 14941>,
			<14609 20589 21106 21857 16937 15939>,
			<14739 20520 21009 21511 18453 17798>,
			<14786 20580 20877 21083 18748 18329>,
			<13815 21940 20644 20373 17554 18145>,
			<12362 23321 20484 19726 16513 17829>,
			<12066 21384 20561 19311 16515 17088>,
			<12143 15748 20823 18965 16591 15971>,
			<12242 13374 21318 18850 16561 15634>,
			<12436 13487 22902 18891 15949 15678>,
			<12735 13611 24181 18979 15387 15721>,
			<12893 13581 23314 19087 16013 15727>,
			<12955 13453 21068 19284 17642 15728>,
			<13026 13394 19739 19709 18471 15827>,
			<13205 13457 19097 21139 18712 16920>,
			<13496 13579 18697 22249 18879 18069>,
			<13748 13765 18521 21910 19072 18334>,
			<13993 14080 18405 20977 19282 18453>,
			<14155 14305 18289 20118 19342 18692>,
			<13965 14441 18160 19051 19194 19459>,
			<13354 14540 18057 18102 19045 20269>,
			<12973 14495 17955 17561 19112 20656>,
			<12842 14254 17694 17209 19295 20885>,
			<12733 13954 15842 17158 18256 19991>,
			<12670 13543 14150 17125 16798 18535>,
			<12363 13234 14096 17626 16436 17531>,
			<12227 13397 14107 17601 16457 16777>,
			<12478 13644 13981 17397 17447 16651>,
			<12006 13698 13940 17555 17565 16279>,
			<11332 13168 14100 17953 16925 15891>,
			<10554 12106 14121 18059 16527 15931>,
			<9684 10624 13641 18539 18324 17134>,
			<9063 9430 12372 19635 20748 18030>,
			<8820 8861 10231 20822 22452 22785>,
			<8820 8861 10231 20822 22452 22785>,
			<8820 8861 10231 20822 22452 22785>;
	};

	qcom,pc-temp-y6-lut {
		qcom,lut-col-legend = <(-10) 0 10 25 40 50>;
		qcom,lut-row-legend = <10000 9800 9600 9400 9200 9000>,
			<8800 8600 8400 8200 8000 7800>,
			<7600 7400 7200 7000 6800 6600>,
			<6400 6200 6000 5800 5600 5400>,
			<5200 5000 4800 4600 4400 4200>,
			<4000 3800 3600 3400 3200 3000>,
			<2800 2600 2400 2200 2000 1800>,
			<1600 1400 1200 1000 900 800>,
			<700 600 500 400 300 200>,
			<100 0>;
		qcom,lut-data = <6191 5540 5245 5077 5027 5018>,
			<6192 5552 5253 5078 5028 5018>,
			<6192 5563 5259 5080 5030 5019>,
			<6192 5572 5264 5081 5031 5020>,
			<6192 5578 5266 5082 5032 5021>,
			<6191 5580 5267 5083 5033 5022>,
			<6178 5579 5266 5084 5035 5023>,
			<6151 5575 5262 5085 5036 5025>,
			<6134 5571 5261 5086 5037 5026>,
			<6125 5567 5260 5088 5039 5027>,
			<6117 5563 5259 5090 5041 5029>,
			<6108 5559 5260 5092 5043 5031>,
			<6098 5555 5261 5095 5046 5032>,
			<6085 5556 5264 5099 5048 5034>,
			<6067 5572 5271 5103 5051 5037>,
			<6045 5586 5276 5107 5054 5039>,
			<6016 5570 5275 5112 5057 5042>,
			<5978 5531 5273 5118 5062 5045>,
			<5954 5507 5267 5124 5067 5049>,
			<5943 5496 5247 5131 5075 5056>,
			<5935 5487 5226 5135 5080 5061>,
			<5929 5477 5214 5119 5069 5052>,
			<5924 5467 5205 5089 5045 5033>,
			<5922 5464 5200 5077 5035 5025>,
			<5927 5464 5198 5074 5032 5022>,
			<5937 5464 5196 5072 5030 5021>,
			<5950 5461 5197 5073 5031 5021>,
			<5971 5454 5197 5075 5033 5023>,
			<5996 5452 5198 5077 5036 5025>,
			<6024 5471 5200 5080 5039 5027>,
			<6056 5502 5201 5083 5042 5031>,
			<6088 5531 5201 5086 5046 5034>,
			<6121 5565 5200 5089 5051 5038>,
			<6155 5602 5201 5091 5052 5039>,
			<6192 5642 5211 5093 5052 5039>,
			<6231 5686 5226 5095 5050 5038>,
			<6266 5737 5242 5093 5047 5035>,
			<6297 5795 5262 5088 5039 5028>,
			<6327 5857 5285 5087 5036 5026>,
			<6356 5924 5311 5088 5037 5027>,
			<6383 5993 5338 5090 5037 5029>,
			<6416 6061 5367 5093 5038 5029>,
			<6455 6130 5398 5098 5039 5029>,
			<6506 6198 5431 5101 5036 5025>,
			<6581 6269 5476 5105 5032 5021>,
			<6785 6342 5512 5105 5038 5028>,
			<6909 6335 5517 5106 5043 5035>,
			<6981 6436 5579 5115 5053 5046>,
			<7448 6574 5662 5128 5065 5057>,
			<8242 6895 5775 5142 5069 5057>,
			<9903 7531 5928 5135 5053 5039>,
			<13734 9115 6217 5133 5043 5032>,
			<24286 14281 6892 5154 5049 5036>,
			<63911 37950 8669 5190 5059 5047>,
			<63911 37950 8669 5190 5059 5047>,
			<63911 37950 8669 5190 5059 5047>;
	};

};
